# dma: IP-XACT component
VLNV spiritconsortium.org:Leon2TLM:dma:1.4

## Bus interfaces (logical=physical port)
AHB_Master: initiator amba.com:AMBA2:AHB:r2p0_6, address space AHB_AS
  PV_TRANS=ahb_master_port
APB_Slave: target amba.com:AMBA2:APB:r2p0_4, memory map APB_MM
  PV_TRANS=apb_slave_port
INT_Master: initiator spiritconsortium.org:busdef.interrupt:interrupt:1.0
  IRQ=int_master_port

## Ports
transactional apb_slave_port
transactional ahb_master_port
out int_master_port

## Address spaces and blocks
AHB_AS: range 4 * (2 ** 30), width 32
APB_MM.apbMemoryMap: base 0, range 16, width width

## Registers
Registers are 32-bit, read-write, no defined reset value unless marked. A register's access mark holds for its fields unless they carry their own. Offsets are from the block's base; lines under a group give offsets from that group; [hi:lo] are bit positions; {n}, {i} and the like mark numbered series; 'fields as' and 'values as' point back to an identical list; <NAME> marks a mode.

## APB_MM.apbMemoryMap
Base 0x00000000
0x00 sourceAddress
0x04 destinationAddress
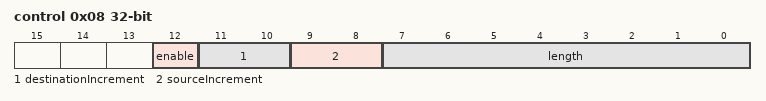
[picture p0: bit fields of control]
0x08 control
  [12] enable wo — Enable transfer
  [11:10] destinationIncrement — 00=no incrment, 01=Byte, 01=half word, 11=Word incrementing of address
  [9:8] sourceIncrement — 00=no incrment, 01=Byte, 01=half word, 11=Word incrementing of address
  [7:0] length — Size of data transfer

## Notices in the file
Copyright (c) 2005, 2006, 2007, 2008, 2009 The SPIRIT Consortium.
This work forms part of a deliverable of The SPIRIT Consortium.
Use of these materials are governed by the legal terms and conditions
outlined in the disclaimer available from www.spiritconsortium.org.
This source file is provided on an AS IS basis.  The SPIRIT
Consortium disclaims any warranty express or implied including
any warranty of merchantability and fitness for use for a
particular purpose.
The user of the source file shall indemnify and hold The SPIRIT
Consortium and its members harmless from any damages or liability.
